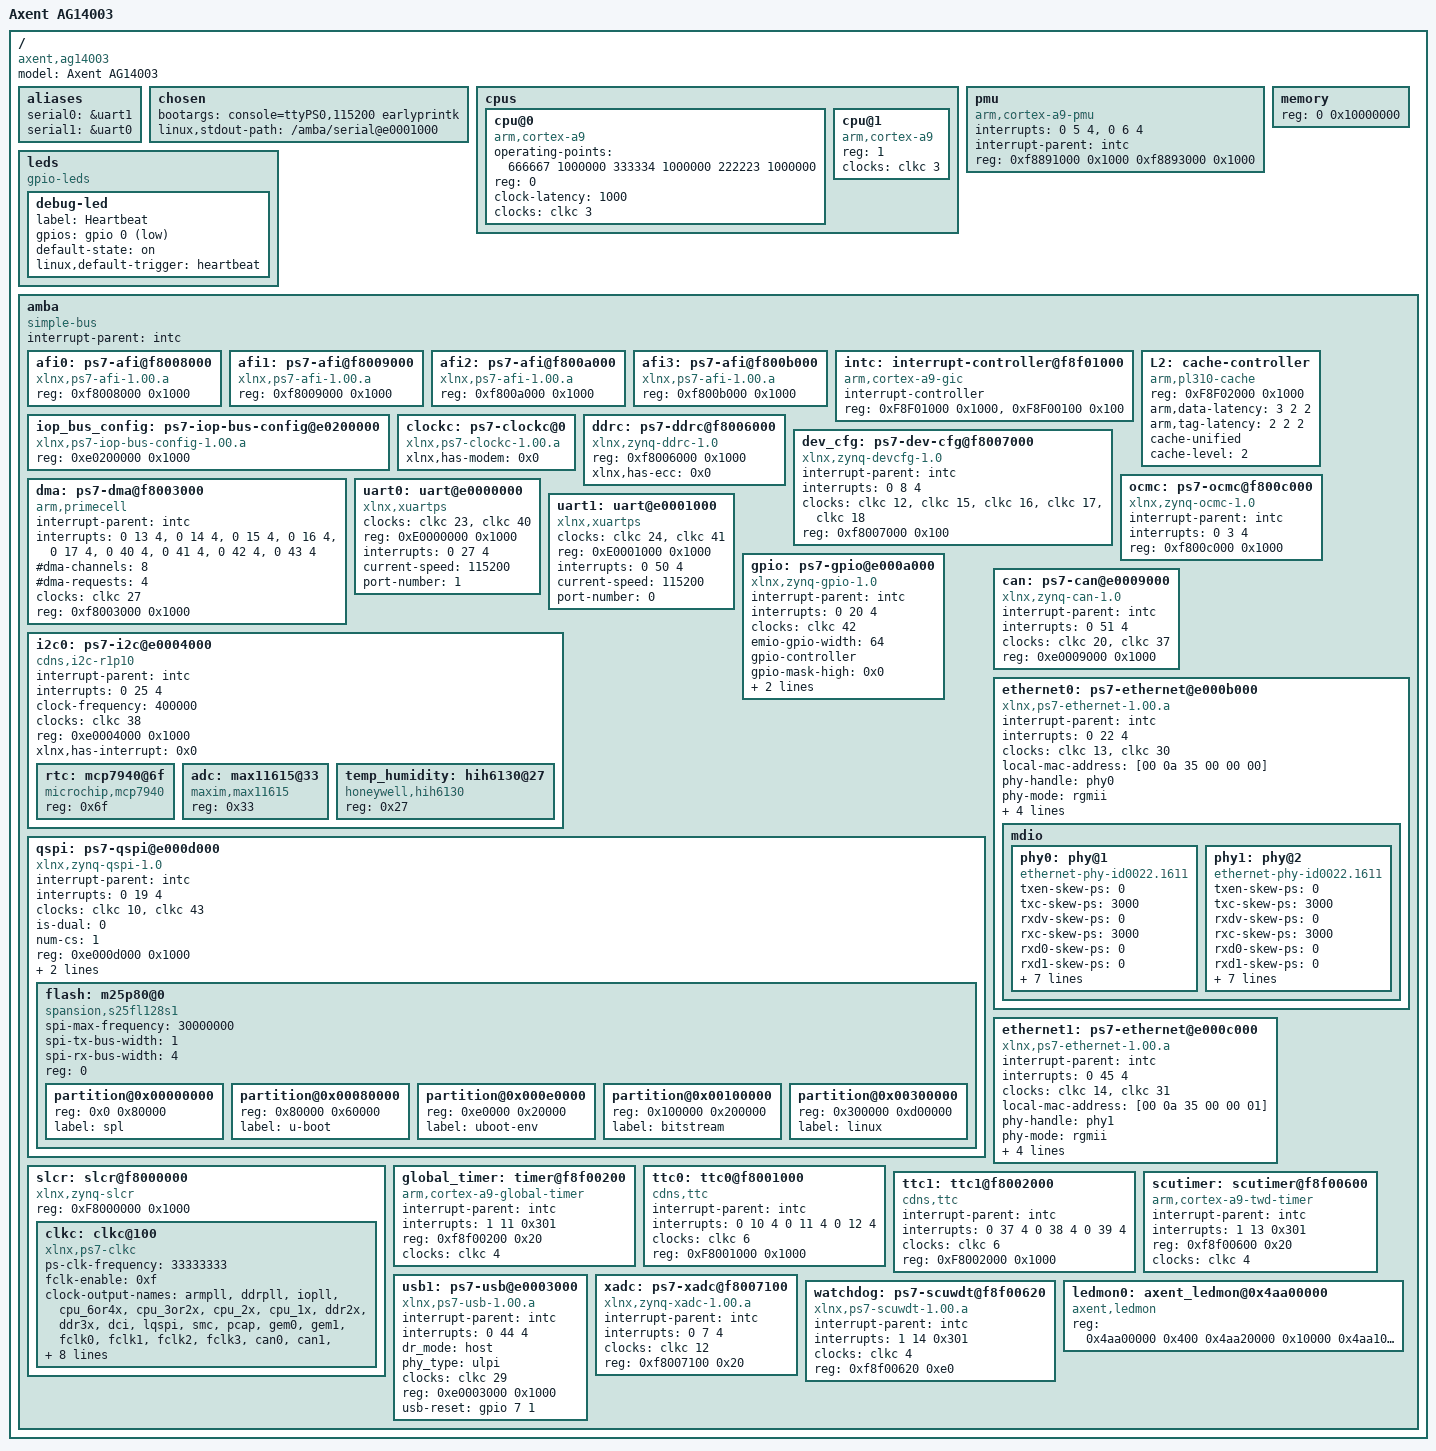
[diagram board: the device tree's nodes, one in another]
/*
 * Copyright (c) 2014 Axent Global
 *
 * Derived from zynq-zed.dts:
 *
 *  Copyright (C) 2011 Xilinx
 *  Copyright (C) 2012 National Instruments Corp.
 *  Copyright (C) 2013 Xilinx
 *
 * This software is licensed under the terms of the GNU General Public
 * License version 2, as published by the Free Software Foundation, and
 * may be copied, distributed, and modified under those terms.
 *
 * This program is distributed in the hope that it will be useful,
 * but WITHOUT ANY WARRANTY; without even the implied warranty of
 * MERCHANTABILITY or FITNESS FOR A PARTICULAR PURPOSE.  See the
 * GNU General Public License for more details.
 */
/dts-v1/;
/include/ "skeleton.dtsi"

/ {
	model = "Axent AG14003";
	compatible = "axent,ag14003", "xlnx,zynq-7000";

    aliases {
		serial0 = &uart1;
		serial1 = &uart0;
	} ;
	
	chosen {
		bootargs = "console=ttyPS0,115200 earlyprintk";
		linux,stdout-path = "/amba/serial@e0001000";
	};

	cpus {
		#address-cells = <1>;
		#size-cells = <0>;

		cpu@0 {
			compatible = "arm,cortex-a9";
			device_type = "cpu";
			operating-points = <666667 1000000 333334 1000000 222223 1000000>;
			reg = <0>;
			clock-latency = <1000>;
			clocks = <&clkc 3>;
		};

		cpu@1 {
			compatible = "arm,cortex-a9";
			device_type = "cpu";
			reg = <1>;
			clocks = <&clkc 3>;
		};
	};

	pmu {
		compatible = "arm,cortex-a9-pmu";
		interrupts = <0 5 4>, <0 6 4>;
		interrupt-parent = <&intc>;
		reg = < 0xf8891000 0x1000 0xf8893000 0x1000 >;
	};
	
	memory {
		device_type = "memory";
		reg = <0 0x10000000>;
	};
	
	leds {
		compatible = "gpio-leds";
		debug-led {
			label = "Heartbeat";
			gpios = <&gpio 0 1>;
			default-state = "on";
			linux,default-trigger = "heartbeat";
		};
	};

	amba {
		compatible = "simple-bus";
		#address-cells = <1>;
		#size-cells = <1>;
		interrupt-parent = <&intc>;
		ranges;

		afi0: ps7-afi@f8008000 {
			compatible = "xlnx,ps7-afi-1.00.a";
			reg = <0xf8008000 0x1000>;
		};
		afi1: ps7-afi@f8009000 {
			compatible = "xlnx,ps7-afi-1.00.a";
			reg = <0xf8009000 0x1000>;
		};
		afi2: ps7-afi@f800a000 {
			compatible = "xlnx,ps7-afi-1.00.a";
			reg = <0xf800a000 0x1000>;
		};
		afi3: ps7-afi@f800b000 {
			compatible = "xlnx,ps7-afi-1.00.a";
			reg = <0xf800b000 0x1000>;
		};

		intc: interrupt-controller@f8f01000 {
			compatible = "arm,cortex-a9-gic";
			#interrupt-cells = <3>;
			#address-cells = <1>;
			interrupt-controller;
			reg = <0xF8F01000 0x1000>,
			      <0xF8F00100 0x100>;
		};

		L2: cache-controller {
			compatible = "arm,pl310-cache";
			reg = <0xF8F02000 0x1000>;
			arm,data-latency = <3 2 2>;
			arm,tag-latency = <2 2 2>;
			cache-unified;
			cache-level = <2>;
		};

		iop_bus_config: ps7-iop-bus-config@e0200000 {
			compatible = "xlnx,ps7-iop-bus-config-1.00.a";
			reg = <0xe0200000 0x1000>;
		};
		
		clockc: ps7-clockc@0 {
			compatible = "xlnx,ps7-clockc-1.00.a";
			xlnx,has-modem = <0x0>;
		};
		
		ddrc: ps7-ddrc@f8006000 {
			compatible = "xlnx,zynq-ddrc-1.0";
			reg = <0xf8006000 0x1000>;
			xlnx,has-ecc = <0x0>;
		};
		
		dev_cfg: ps7-dev-cfg@f8007000 {
		    interrupt-parent = <&intc>;
			interrupts = <0 8 4>;
			clock-names = "ref_clk", "fclk0", "fclk1", "fclk2", "fclk3";
			clocks = <&clkc 12>, <&clkc 15>, <&clkc 16>, <&clkc 17>, <&clkc 18>;
			compatible = "xlnx,zynq-devcfg-1.0";
			reg = <0xf8007000 0x100>;
		};
		
		ocmc: ps7-ocmc@f800c000 {
		    interrupt-parent = <&intc>;
			interrupts = <0 3 4>;
			compatible = "xlnx,zynq-ocmc-1.0";
			reg = <0xf800c000 0x1000>;
		};
		
		dma: ps7-dma@f8003000 {
		    interrupt-parent = <&intc>;
			interrupts = <0 13 4>, <0 14 4>, <0 15 4>, <0 16 4>, <0 17 4>, <0 40 4>, <0 41 4>, <0 42 4>, <0 43 4>;
			#dma-cells = <1>;
			#dma-channels = <8>;
			#dma-requests = <4>;
			clock-names = "apb_pclk";
			clocks = <&clkc 27>;
			compatible = "arm,primecell", "arm,pl330";
			interrupt-names = "abort", "dma0", "dma1", "dma2", "dma3",
				"dma4", "dma5", "dma6", "dma7";
			reg = <0xf8003000 0x1000>;
		};

		uart0: uart@e0000000 {
			compatible = "xlnx,xuartps";
			clocks = <&clkc 23>, <&clkc 40>;
			clock-names = "ref_clk", "aper_clk";
			reg = <0xE0000000 0x1000>;
			interrupts = <0 27 4>;
			current-speed = <115200>;
			port-number = <1>;
		};

		uart1: uart@e0001000 {
			compatible = "xlnx,xuartps";
			clocks = <&clkc 24>, <&clkc 41>;
			clock-names = "ref_clk", "aper_clk";
			reg = <0xE0001000 0x1000>;
			interrupts = <0 50 4>;
			current-speed = <115200>;
			port-number = <0>;
		};
		
		gpio: ps7-gpio@e000a000 {
		    interrupt-parent = <&intc>;
			interrupts = <0 20 4>;
			#gpio-cells = <2>;
			clocks = <&clkc 42>;
			compatible = "xlnx,zynq-gpio-1.0";
			emio-gpio-width = <64>;
			gpio-controller ;
			gpio-mask-high = <0x0>;
			gpio-mask-low = <0x5600>;
			reg = <0xe000a000 0x1000>;
		};
		
		i2c0: ps7-i2c@e0004000 {
		    interrupt-parent = <&intc>;
			interrupts = <0 25 4>;
			clock-frequency = <400000>;
			clocks = <&clkc 38>;
			compatible = "cdns,i2c-r1p10";
			reg = <0xe0004000 0x1000>;
			xlnx,has-interrupt = <0x0>;
			#address-cells = <1>;
			#size-cells = <0>;
			
			rtc: mcp7940@6f {
	            compatible = "microchip,mcp7940";
	            reg = <0x6f>;
	        };
	        adc: max11615@33 {
	            compatible = "maxim,max11615";
	            reg = <0x33>;
	        };
	        temp_humidity: hih6130@27 {
	            compatible = "honeywell,hih6130";
	            reg = <0x27>;
	        };
		};
		
        qspi: ps7-qspi@e000d000 {
            interrupt-parent = <&intc>;
            interrupts = <0 19 4>;
			clock-names = "ref_clk", "pclk";
			clocks = <&clkc 10>, <&clkc 43>;
			compatible = "xlnx,zynq-qspi-1.0";
			is-dual = <0>;
			num-cs = <1>;
			reg = <0xe000d000 0x1000>;
			xlnx,fb-clk = <0x0>;
			xlnx,qspi-mode = <0x0>;
			#address-cells = <1>;
			#size-cells = <0>;
			flash: m25p80@0 {
		        compatible = "spansion,s25fl128s1";
		        spi-max-frequency = <30000000>;
		        spi-tx-bus-width = <1>;
				spi-rx-bus-width = <4>;
				#address-cells = <1>;
				#size-cells = <1>;
		        reg = <0>;
		        partition@0x00000000 {
			        reg = <0x0 0x80000>;
			        label = "spl";
		        };
		        partition@0x00080000 {
			        reg = <0x80000 0x60000>;
			        label = "u-boot";
		        };
		        partition@0x000e0000 {
			        reg = <0xe0000 0x20000>;
			        label = "uboot-env";
		        };
		        partition@0x00100000 {
			        reg = <0x100000 0x200000>;
			        label = "bitstream";
		        };
		        partition@0x00300000 {
			        reg = <0x300000 0xd00000>;
			        label = "linux";
		        };
	        };
		};
		
		can: ps7-can@e0009000 {
		    interrupt-parent = <&intc>;
			interrupts = <0 51 4>;
			clock-names = "ref_clk", "aper_clk";
			clocks = <&clkc 20>, <&clkc 37>;
			compatible = "xlnx,zynq-can-1.0";
			reg = <0xe0009000 0x1000>;
		};
		
		ethernet0: ps7-ethernet@e000b000 {
		    interrupt-parent = <&intc>;
			interrupts = <0 22 4>;
			#address-cells = <1>;
			#size-cells = <0>;
			clock-names = "ref_clk", "aper_clk";
			clocks = <&clkc 13>, <&clkc 30>;
			compatible = "xlnx,ps7-ethernet-1.00.a";
			local-mac-address = [00 0a 35 00 00 00];
			phy-handle = <&phy0>;
			phy-mode = "rgmii";
			reg = <0xe000b000 0x1000>;
			xlnx,eth-mode = <0x1>;
			xlnx,has-mdio = <0x1>;
			xlnx,ptp-enet-clock = <111111115>;
			mdio {
				#address-cells = <1>;
				#size-cells = <0>;
				phy0: phy@1 {
					compatible = "ethernet-phy-id0022.1611",
                                 "ethernet-phy-ieee802.3-c22";
				    txen-skew-ps = <0>;
	                txc-skew-ps = <3000>;
	                rxdv-skew-ps = <0>;
	                rxc-skew-ps = <3000>;
	                rxd0-skew-ps = <0>;
	                rxd1-skew-ps = <0>;
	                rxd2-skew-ps = <0>;
	                rxd3-skew-ps = <0>;
	                txd0-skew-ps = <0>;
	                txd1-skew-ps = <0>;
	                txd2-skew-ps = <0>;
	                txd3-skew-ps = <0>;
					device_type = "ethernet-phy";
			        reg = <1>;
				} ;
				phy1: phy@2 {
					compatible = "ethernet-phy-id0022.1611",
                                 "ethernet-phy-ieee802.3-c22";
				    txen-skew-ps = <0>;
	                txc-skew-ps = <3000>;
	                rxdv-skew-ps = <0>;
	                rxc-skew-ps = <3000>;
	                rxd0-skew-ps = <0>;
	                rxd1-skew-ps = <0>;
	                rxd2-skew-ps = <0>;
	                rxd3-skew-ps = <0>;
	                txd0-skew-ps = <0>;
	                txd1-skew-ps = <0>;
	                txd2-skew-ps = <0>;
	                txd3-skew-ps = <0>;
					device_type = "ethernet-phy";
			        reg = <2>;
				} ;
			} ;
		} ;
		ethernet1: ps7-ethernet@e000c000 {
		    interrupt-parent = <&intc>;
			interrupts = <0 45 4>;
			#address-cells = <1>;
			#size-cells = <0>;
			clock-names = "ref_clk", "aper_clk";
			clocks = <&clkc 14>, <&clkc 31>;
			compatible = "xlnx,ps7-ethernet-1.00.a";
			local-mac-address = [00 0a 35 00 00 01];
			phy-handle = <&phy1>;
			phy-mode = "rgmii";
			reg = <0xe000c000 0x1000>;
			xlnx,eth-mode = <0x1>;
			xlnx,has-mdio = <0x0>;
			xlnx,ptp-enet-clock = <111111115>;
		} ;
        /*
		sdhci0: ps7-sdhci@e0100000 {
			compatible = "arasan,sdhci-8.9a";
			clock-names = "clk_xin", "clk_ahb";
			clocks = <&clkc 21>, <&clkc 32>;
			interrupt-parent = <&intc>;
			interrupts = <0 24 4>;
			reg = <0xe0100000 0x1000>;
		};
        */
		slcr: slcr@f8000000 {
			#address-cells = <1>;
			#size-cells = <1>;
			compatible = "xlnx,zynq-slcr", "syscon";
			reg = <0xF8000000 0x1000>;
			ranges;
			clkc: clkc@100 {
				#clock-cells = <1>;
				compatible = "xlnx,ps7-clkc";
				ps-clk-frequency = <33333333>;
				fclk-enable = <0xf>;
				clock-output-names = "armpll", "ddrpll", "iopll", "cpu_6or4x",
						"cpu_3or2x", "cpu_2x", "cpu_1x", "ddr2x", "ddr3x",
						"dci", "lqspi", "smc", "pcap", "gem0", "gem1",
						"fclk0", "fclk1", "fclk2", "fclk3", "can0", "can1",
						"sdio0", "sdio1", "uart0", "uart1", "spi0", "spi1",
						"dma", "usb0_aper", "usb1_aper", "gem0_aper",
						"gem1_aper", "sdio0_aper", "sdio1_aper",
						"spi0_aper", "spi1_aper", "can0_aper", "can1_aper",
						"i2c0_aper", "i2c1_aper", "uart0_aper", "uart1_aper",
						"gpio_aper", "lqspi_aper", "smc_aper", "swdt",
						"dbg_trc", "dbg_apb";
				reg = <0x100 0x100>;
			};
		};

		global_timer: timer@f8f00200 {
		    interrupt-parent = <&intc>;
			interrupts = <1 11 0x301>;
			compatible = "arm,cortex-a9-global-timer";
			reg = <0xf8f00200 0x20>;
			clocks = <&clkc 4>;
		};

		ttc0: ttc0@f8001000 {
			interrupt-parent = <&intc>;
			interrupts = < 0 10 4 0 11 4 0 12 4 >;
			compatible = "cdns,ttc";
			clocks = <&clkc 6>;
			reg = <0xF8001000 0x1000>;
		};

		ttc1: ttc1@f8002000 {
			interrupt-parent = <&intc>;
			interrupts = < 0 37 4 0 38 4 0 39 4 >;
			compatible = "cdns,ttc";
			clocks = <&clkc 6>;
			reg = <0xF8002000 0x1000>;
		};
		
		scutimer: scutimer@f8f00600 {
			interrupt-parent = <&intc>;
			interrupts = < 1 13 0x301 >;
			compatible = "arm,cortex-a9-twd-timer";
			reg = < 0xf8f00600 0x20 >;
			clocks = <&clkc 4>;
		};
		
		usb1: ps7-usb@e0003000 {
		    interrupt-parent = <&intc>;
			interrupts = <0 44 4>;
			compatible = "xlnx,ps7-usb-1.00.a", "xlnx,zynq-usb-1.00.a";
			dr_mode = "host";
			phy_type = "ulpi";
			clocks = <&clkc 29>;
			reg = <0xe0003000 0x1000>;
			usb-reset = <&gpio 7 1>;
		};
		
		xadc: ps7-xadc@f8007100 {
		    interrupt-parent = <&intc>;
		    interrupts = <0 7 4>;
			compatible = "xlnx,zynq-xadc-1.00.a";
			clocks = <&clkc 12>;
			reg = <0xf8007100 0x20>;
		};
		
		watchdog: ps7-scuwdt@f8f00620 {
		    interrupt-parent = <&intc>;
			interrupts = <1 14 0x301>;
			clocks = <&clkc 4>;
			compatible = "xlnx,ps7-scuwdt-1.00.a";
			device_type = "watchdog";
			reg = <0xf8f00620 0xe0>;
		};
		
		ledmon0: axent_ledmon@0x4aa00000 {
		    compatible = "axent,ledmon";
		    reg = <0x4aa00000 0x400     /* Registers */
		           0x4aa20000 0x10000   /* Framebuffer */
		           0x4aa10000 0x10000>; /* Pixelmap */
		};
	};
};
